# MKL46Z4 register map
Vendor: Freescale Semiconductor, Inc.; File version: 1.6
CPU: CM0PLUS r0p0, little endian, no MPU, no FPU, 0x2 interrupt priority bits, 0x0 interrupts
Registers are 32-bit, read-write, reset 0x0 unless marked. A register's access mark holds for its fields unless they carry their own. Offsets are from the block's base; [hi:lo] are bit positions; {n}, {i} and the like mark numbered series; 'fields as' and 'values as' point back to an identical list.

## TSI0 — Touch sense input
Base 0x40045000; register names take the prefix TSI0_
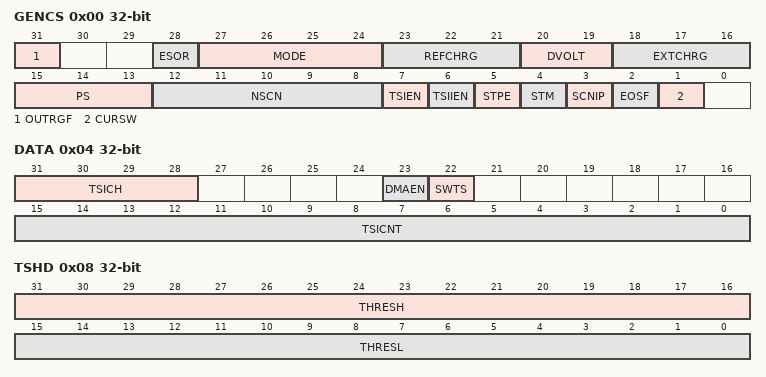
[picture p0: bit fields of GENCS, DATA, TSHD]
0x00 GENCS — TSI General Control and Status Register
  [31] OUTRGF — Out of Range Flag.
  [28] ESOR — End-of-scan or Out-of-Range Interrupt Selection
    0=Out-of-range interrupt is allowed; 1=End-of-scan interrupt is allowed
  [27:24] MODE — TSI analog modes setup and status bits.
    0=Set TSI in capacitive sensing(non-noise detection) mode; 4=Set TSI analog to work in single threshold noise detection mode and the frequency limitation circuit is disabled; 8=Set TSI analog to work in single threshold noise detection mode and the frequency limitation circuit is enabled to work in higher frequencies operations; 12=Set TSI analog to work in automatic noise detection mode
  [23:21] REFCHRG
    0=500 nA; 1=1 uA; 2=2 uA; 3=4 uA; 4=8 uA; 5=16 uA; 6=32 uA; 7=64 uA
  [20:19] DVOLT
    0=DV = 1.03 V; VP = 1.33 V; Vm = 0.30 V; 1=DV = 0.73 V; VP = 1.18 V; Vm = 0.45 V; 2=DV = 0.43 V; VP = 1.03 V; Vm = 0.60 V; 3=DV = 0.29 V; VP = 0.95 V; Vm = 0.67 V
  [18:16] EXTCHRG
    values as REFCHRG
  [15:13] PS
    0=Electrode Oscillator Frequency divided by 1; 1=Electrode Oscillator Frequency divided by 2; 2=Electrode Oscillator Frequency divided by 4; 3=Electrode Oscillator Frequency divided by 8; 4=Electrode Oscillator Frequency divided by 16; 5=Electrode Oscillator Frequency divided by 32; 6=Electrode Oscillator Frequency divided by 64; 7=Electrode Oscillator Frequency divided by 128
  [12:8] NSCN
    0=Once per electrode; 1=Twice per electrode; {v}={v+1} times per electrode (v=2..31)
  [7] TSIEN — Touch Sensing Input Module Enable
    0=TSI module disabled; 1=TSI module enabled
  [6] TSIIEN — Touch Sensing Input Interrupt Enable
    0=TSI interrupt is disabled; 1=TSI interrupt is enabled
  [5] STPE — TSI STOP Enable
    0=TSI is disabled when MCU goes into low power mode; 1=Allows TSI to continue running in all low power modes
  [4] STM — Scan Trigger Mode
    0=Software trigger scan; 1=Hardware trigger scan
  [3] SCNIP ro — Scan In Progress Status
    0=No scan in progress; 1=Scan in progress
  [2] EOSF — End of Scan Flag
    0=Scan not complete; 1=Scan complete
  [1] CURSW
    0=The current source pair are not swapped; 1=The current source pair are swapped
0x04 DATA — TSI DATA Register
  [31:28] TSICH
    {v}=Channel {v} (v=0..15)
  [23] DMAEN — DMA Transfer Enabled
    0=Interrupt is selected when the interrupt enable bit is set and the corresponding TSI events assert; 1=DMA transfer request is selected when the interrupt enable bit is set and the corresponding TSI events assert
  [22] SWTS wo — Software Trigger Start
    0=No effect; 1=Start a scan to determine which channel is specified by TSI_DATA[TSICH]
  [15:0] TSICNT ro — TSI Conversion Counter Value
0x08 TSHD — TSI Threshold Register
  [31:16] THRESH — TSI Wakeup Channel High-threshold
  [15:0] THRESL — TSI Wakeup Channel Low-threshold

## OSC0 — Oscillator
Base 0x40065000; register names take the prefix OSC0_
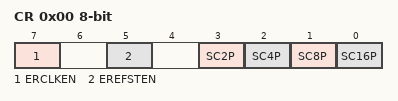
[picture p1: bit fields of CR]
0x00 CR 8-bit — OSC Control Register
  [7] ERCLKEN — External Reference Enable
    0=External reference clock is inactive; 1=External reference clock is enabled
  [5] EREFSTEN — External Reference Stop Enable
    0=External reference clock is disabled in Stop mode; 1=External reference clock stays enabled in Stop mode if ERCLKEN is set before entering Stop mode
  [3] SC2P — Oscillator 2 pF Capacitor Load Configure
    0=Disable the selection; 1=Add 2 pF capacitor to the oscillator load
  [2] SC4P — Oscillator 4 pF Capacitor Load Configure
    0=Disable the selection; 1=Add 4 pF capacitor to the oscillator load
  [1] SC8P — Oscillator 8 pF Capacitor Load Configure
    0=Disable the selection; 1=Add 8 pF capacitor to the oscillator load
  [0] SC16P — Oscillator 16 pF Capacitor Load Configure
    0=Disable the selection; 1=Add 16 pF capacitor to the oscillator load
